VERSION ""

NS_ :

BS_:

BU_: Button_Panel_8 Joystick_JS6000 Display ESX_4CM_A Engine

BO_ 3221225472 VECTOR__INDEPENDENT_SIG_MSG: 0 Vector__XXX
 SG_ Button_State_09 : 24|2@1+ (1,0) [0|0] ""  ESX_4CM_A
 SG_ Button_State_10 : 26|2@1+ (1,0) [0|0] ""  ESX_4CM_A
 SG_ Button_State_11 : 28|2@1+ (1,0) [0|0] ""  ESX_4CM_A
 SG_ Button_State_12 : 30|2@1+ (1,0) [0|0] ""  ESX_4CM_A
 SG_ Joystick1XAxisNeutralPosStatus : 0|2@1+ (1,0) [0|3] ""  ESX_4CM_A
 SG_ Jystck1XAxsLvrLftNgtvePosStatus : 2|2@1+ (1,0) [0|3] ""  ESX_4CM_A
 SG_ Jystck1XAxsLvrRghtPstvPosStatus : 4|2@1+ (1,0) [0|3] ""  ESX_4CM_A
 SG_ Joystick1XAxisDetentPosStatus : 38|2@1+ (1,0) [0|3] ""  ESX_4CM_A
 SG_ Joystick1XAxisPos : 6|10@1+ (0.1,0) [0|102] "%"  ESX_4CM_A
 SG_ Joystick1Button12PressedStatus : 56|2@1+ (1,0) [0|3] ""  ESX_4CM_A
 SG_ Joystick1Button11PressedStatus : 58|2@1+ (1,0) [0|3] ""  ESX_4CM_A
 SG_ Joystick1Button10PressedStatus : 60|2@1+ (1,0) [0|3] ""  ESX_4CM_A
 SG_ Joystick1Button9PressedStatus : 62|2@1+ (1,0) [0|3] ""  ESX_4CM_A
 SG_ Joystick1Button8PressedStatus : 48|2@1+ (1,0) [0|3] ""  ESX_4CM_A
 SG_ Joystick1Button7PressedStatus : 50|2@1+ (1,0) [0|3] ""  ESX_4CM_A
 SG_ Joystick1YAxisDetentPosStatus : 36|2@1+ (1,0) [0|3] ""  ESX_4CM_A

BO_ 2565841155 E31_LIGHTS: 8 ESX_4CM_A
 SG_ BTN08_IND_SR m177 : 16|8@1+ (1,0) [0|0] ""  Button_Panel_8
 SG_ BTN01_IND_Aux1 m176 : 8|8@1+ (1,0) [0|0] ""  Button_Panel_8
 SG_ E1_IND_MUX M : 0|8@1+ (1,0) [0|0] ""  Button_Panel_8
 SG_ BTN_BACKLIGHT m136 : 8|1@1+ (1,0) [0|0] ""  Button_Panel_8
 SG_ BTN02_IND_AutoUL m176 : 16|8@1+ (1,0) [0|0] "" Vector__XXX
 SG_ BTN03_IND_SB_OP m176 : 24|8@1+ (1,0) [0|0] "" Vector__XXX
 SG_ BTN04_IND_Lights m176 : 32|8@1+ (1,0) [0|0] "" Vector__XXX
 SG_ BTN05_IND_PA m176 : 40|8@1+ (1,0) [0|0] "" Vector__XXX
 SG_ BTN06_IND_ManUL m176 : 48|8@1+ (1,0) [0|0] "" Vector__XXX
 SG_ BTN07_IND_SB_CL m176 : 56|8@1+ (1,0) [0|0] "" Vector__XXX

BO_ 2566889889 E1_BTN_STATUS: 8 Button_Panel_8
 SG_ BTN01_Aux1 m32 : 8|2@1+ (1,0) [0|0] ""  ESX_4CM_A
 SG_ BTN08_SR m32 : 22|2@1+ (1,0) [0|0] ""  ESX_4CM_A
 SG_ BTN07_SB_CL m32 : 20|2@1+ (1,0) [0|0] ""  ESX_4CM_A
 SG_ BNT06_ManUL m32 : 18|2@1+ (1,0) [0|0] ""  ESX_4CM_A
 SG_ BTN05_PA m32 : 16|2@1+ (1,0) [0|0] ""  ESX_4CM_A
 SG_ BTN04_Lights m32 : 14|2@1+ (1,0) [0|0] ""  ESX_4CM_A
 SG_ BTN03_SB_OP m32 : 12|2@1+ (1,0) [0|0] ""  ESX_4CM_A
 SG_ BTN02_AutoUL m32 : 10|2@1+ (1,0) [0|0] ""  ESX_4CM_A
 SG_ MUX M : 0|8@1+ (1,0) [0|0] ""  ESX_4CM_A

BO_ 2566849565 DISP_CMD2: 8 Display
 SG_ PROP_SetCCMax : 32|1@1+ (1,0) [0|0] ""  ESX_4CM_A
 SG_ FS_SpeedCmd : 56|8@1+ (1,0) [0|0] "%"  ESX_4CM_A

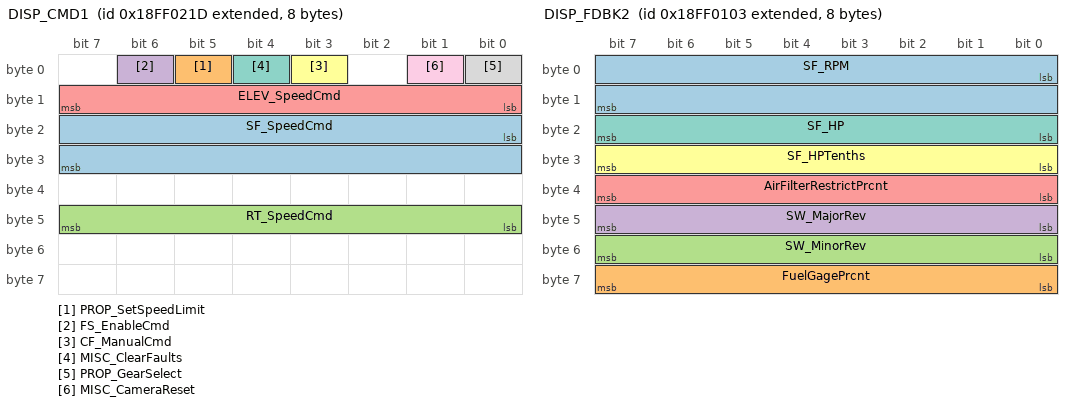
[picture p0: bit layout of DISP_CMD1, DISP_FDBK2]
BO_ 2566849053 DISP_CMD1: 8 Display
 SG_ SF_SpeedCmd : 16|16@1+ (1,0) [0|10000] "RPM"  ESX_4CM_A
 SG_ PROP_SetSpeedLimit : 5|1@1+ (1,0) [0|0] ""  ESX_4CM_A
 SG_ RT_SpeedCmd : 40|8@1+ (1,0) [0|100] "%"  ESX_4CM_A
 SG_ FS_EnableCmd : 6|1@1+ (1,0) [0|0] ""  ESX_4CM_A
 SG_ ELEV_SpeedCmd : 8|8@1+ (1,0) [0|100] "%"  ESX_4CM_A
 SG_ CF_ManualCmd : 3|1@1+ (1,0) [0|0] ""  ESX_4CM_A
 SG_ MISC_ClearFaults : 4|1@1+ (1,0) [0|0] ""  ESX_4CM_A
 SG_ PROP_GearSelect : 0|1@1+ (1,0) [0|0] ""  ESX_4CM_A
 SG_ MISC_CameraReset : 1|1@1+ (1,0) [0|0] ""  ESX_4CM_A

BO_ 2566848515 DISP_FDBK1: 8 ESX_4CM_A
 SG_ HYDOIL_Temp : 48|16@1+ (1,0) [0|255] "degrees C" Vector__XXX
 SG_ HYDOIL_LevelLow : 20|1@1+ (1,0) [0|1] ""  Display
 SG_ HC_ReliefPressure : 19|1@1+ (1,0) [0|1] ""  Display
 SG_ JS_NeutralState : 18|1@1+ (1,0) [0|1] ""  Display
 SG_ CF_Sen3OvrTmp : 47|1@1+ (1,0) [0|1] ""  Display
 SG_ CD_Sen2OvrTmp : 46|1@1+ (1,0) [0|1] ""  Display
 SG_ CF_Sen1OvrTmp : 45|1@1+ (1,0) [0|1] ""  Display
 SG_ CF_ManualStatus : 44|1@1+ (1,0) [0|1] ""  Display
 SG_ CF_DIR : 43|1@1+ (1,0) [0|1] ""  Display
 SG_ PROP_SpeedLimitStatus : 41|1@1+ (1,0) [0|1] ""  Display
 SG_ SR_Status : 39|1@1+ (1,0) [0|1] ""  Display
 SG_ AUGER_Status : 38|1@1+ (1,0) [0|1] ""  Display
 SG_ SHAFT_Status : 37|1@1+ (1,0) [0|1] ""  Display
 SG_ LIGHTS_WORKStatus : 36|1@1+ (1,0) [0|1] ""  Display
 SG_ LIGHTS_HDLTStatus : 35|1@1+ (1,0) [0|1] ""  Display
 SG_ ENGINE_Status : 34|1@1+ (1,0) [0|1] ""  Display
 SG_ ELEV_Status : 33|1@1+ (1,0) [0|1] ""  Display
 SG_ SF_Status : 32|1@1+ (1,0) [0|1] ""  Display
 SG_ PROP_SpeedX10 : 24|8@1+ (1,0) [0|0] "MPH x 10"  Display
 SG_ PROP_NeutralSafeInd : 23|1@1+ (1,0) [0|1] ""  Display
 SG_ MISC_BrakeStatus : 22|1@1+ (1,0) [0|1] ""  Display
 SG_ MISC_DoorStatus : 21|1@1+ (1,0) [0|1] ""  Display
 SG_ FUEL_LevelLow : 17|1@1+ (1,0) [0|1] ""  Display
 SG_ AIRFILT_ServiceRqd : 16|1@1+ (1,0) [0|1] ""  Display
 SG_ FUEL_FuelGage2 : 8|8@1+ (1,0) [0|0] "UINT8"  Display
 SG_ AIRFILT_Restriction : 0|8@1+ (1,0) [0|0] "UINT8"  Display

BO_ 2566848771 DISP_FDBK2: 8 ESX_4CM_A
 SG_ SF_RPM : 0|16@1- (1,0) [0|0] "RPM"  Display
 SG_ FuelGagePrcnt : 56|8@1+ (1,0) [0|0] "%"  Display
 SG_ SW_MinorRev : 48|8@1- (1,0) [0|0] ""  Display
 SG_ SW_MajorRev : 40|8@1- (1,0) [0|0] ""  Display
 SG_ AirFilterRestrictPrcnt : 32|8@1+ (1,0) [0|0] "%"  Display
 SG_ SF_HPTenths : 24|8@1- (1,0) [0|0] ""  Display
 SG_ SF_HP : 16|8@1- (1,0) [0|0] ""  Display

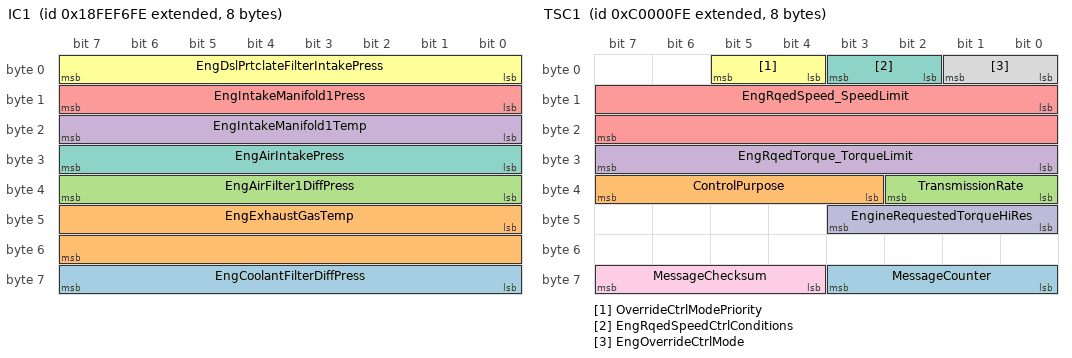
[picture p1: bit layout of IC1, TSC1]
BO_ 2566846206 IC1: 8 Engine
 SG_ EngCoolantFilterDiffPress : 56|8@1+ (0.5,0) [0|125] "kPa"  ESX_4CM_A
 SG_ EngExhaustGasTemp : 40|16@1+ (0.03125,-273) [4294967023|1734.96875] "deg C"  ESX_4CM_A
 SG_ EngAirFilter1DiffPress : 32|8@1+ (0.05,0) [0|12.5] "kPa"  ESX_4CM_A
 SG_ EngIntakeManifold1Temp : 16|8@1+ (1,-40) [4294967256|210] "deg C"  ESX_4CM_A
 SG_ EngIntakeManifold1Press : 8|8@1+ (2,0) [0|500] "kPa"  ESX_4CM_A
 SG_ EngDslPrtclateFilterIntakePress : 0|8@1+ (0.5,0) [0|125] "kPa"  ESX_4CM_A
 SG_ EngAirIntakePress : 24|8@1+ (2,0) [0|500] "kPa"  ESX_4CM_A

BO_ 2348810494 TSC1: 8 ESX_4CM_A
 SG_ MessageCounter : 56|4@1+ (1,0) [0|15] "" Vector__XXX
 SG_ ControlPurpose : 35|5@1+ (1,0) [0|31] "" Vector__XXX
 SG_ TransmissionRate : 32|3@1+ (1,0) [0|7] "" Vector__XXX
 SG_ EngRqedTorque_TorqueLimit : 24|8@1+ (1,-125) [4294967171|125] "%" Vector__XXX
 SG_ EngRqedSpeed_SpeedLimit : 8|16@1+ (0.125,0) [0|8031.875] "rpm"  Engine
 SG_ OverrideCtrlModePriority : 4|2@1+ (1,0) [0|3] "" Vector__XXX
 SG_ EngRqedSpeedCtrlConditions : 2|2@1+ (1,0) [0|3] "" Vector__XXX
 SG_ EngOverrideCtrlMode : 0|2@1+ (1,0) [0|3] "" Vector__XXX
 SG_ MessageChecksum : 60|4@1+ (1,0) [0|15] "" Vector__XXX
 SG_ EngineRequestedTorqueHiRes : 40|4@1+ (0.125,0) [0|0.875] "%" Vector__XXX

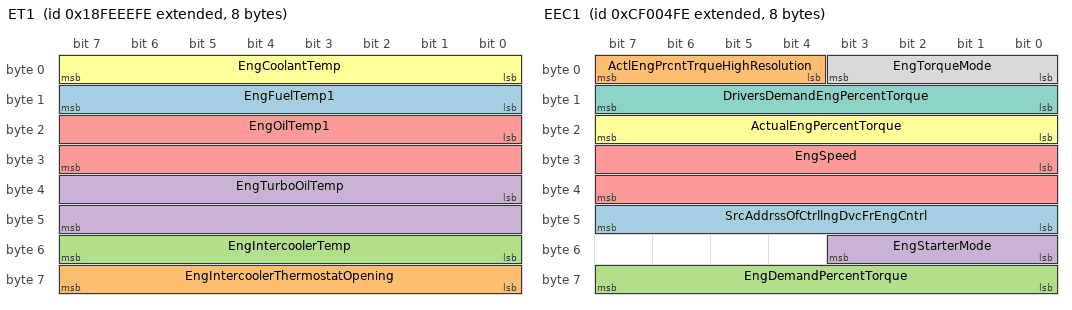
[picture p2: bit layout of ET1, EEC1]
BO_ 2566844158 ET1: 8 Engine
 SG_ EngFuelTemp1 : 8|8@1+ (1,-40) [4294967256|210] "deg C"  ESX_4CM_A
 SG_ EngIntercoolerThermostatOpening : 56|8@1+ (0.4,0) [0|100] "%"  ESX_4CM_A
 SG_ EngIntercoolerTemp : 48|8@1+ (1,-40) [4294967256|210] "deg C"  ESX_4CM_A
 SG_ EngTurboOilTemp : 32|16@1+ (0.03125,-273) [4294967023|1734.96875] "deg C"  ESX_4CM_A
 SG_ EngOilTemp1 : 16|16@1+ (0.03125,-273) [4294967023|1734.96875] "deg C"  ESX_4CM_A
 SG_ EngCoolantTemp : 0|8@1+ (0.03125,-273) [4294967023|-265.03125] "deg C"  ESX_4CM_A

BO_ 2364540158 EEC1: 8 Engine
 SG_ SrcAddrssOfCtrllngDvcFrEngCntrl : 40|8@1+ (1,0) [0|255] "" Vector__XXX
 SG_ ActlEngPrcntTrqueHighResolution : 4|4@1+ (0.125,0) [0|0.875] "%" Vector__XXX
 SG_ EngDemandPercentTorque : 56|8@1+ (1,-125) [4294967171|125] "%" Vector__XXX
 SG_ EngStarterMode : 48|4@1+ (1,0) [0|15] "" Vector__XXX
 SG_ EngSpeed : 24|16@1+ (0.125,0) [0|8031.875] "rpm"  ESX_4CM_A,Display
 SG_ ActualEngPercentTorque : 16|8@1+ (1,-125) [4294967171|125] "%" Vector__XXX
 SG_ DriversDemandEngPercentTorque : 8|8@1+ (1,-125) [4294967171|125] "%" Vector__XXX
 SG_ EngTorqueMode : 0|4@1+ (1,0) [0|15] "" Vector__XXX

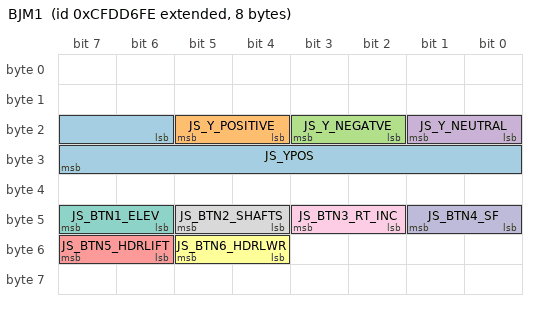
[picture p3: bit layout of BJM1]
BO_ 2365445886 BJM1: 8 Joystick_JS6000
 SG_ JS_YPOS : 22|10@1+ (0.1,0) [0|102] "%"  ESX_4CM_A
 SG_ JS_Y_POSITIVE : 20|2@1+ (1,0) [0|3] ""  ESX_4CM_A
 SG_ JS_Y_NEGATVE : 18|2@1+ (1,0) [0|3] ""  ESX_4CM_A
 SG_ JS_Y_NEUTRAL : 16|2@1+ (1,0) [0|3] ""  ESX_4CM_A
 SG_ JS_BTN5_HDRLIFT : 54|2@1+ (1,0) [0|3] ""  ESX_4CM_A
 SG_ JS_BTN6_HDRLWR : 52|2@1+ (1,0) [0|3] ""  ESX_4CM_A
 SG_ JS_BTN1_ELEV : 46|2@1+ (1,0) [0|3] ""  ESX_4CM_A
 SG_ JS_BTN2_SHAFTS : 44|2@1+ (1,0) [0|3] ""  ESX_4CM_A
 SG_ JS_BTN3_RT_INC : 42|2@1+ (1,0) [0|3] ""  ESX_4CM_A
 SG_ JS_BTN4_SF : 40|2@1+ (1,0) [0|3] ""  ESX_4CM_A

CM_ SG_ 3221225472 Joystick1XAxisNeutralPosStatus "Reports when the current joystick position is in the neutral position for that axis of travel.";
CM_ SG_ 3221225472 Jystck1XAxsLvrLftNgtvePosStatus "Reports when the current joystick position is on the negative travel side (back, left, counterclockwise, down) relative to the";
CM_ SG_ 3221225472 Jystck1XAxsLvrRghtPstvPosStatus "Reports when the current joystick position is on the positive travel side (forward, right, clockwise, up) relative to the";
CM_ SG_ 3221225472 Joystick1XAxisDetentPosStatus "Reports when the current joystick position is in the detent position for that axis of travel.";
CM_ SG_ 3221225472 Joystick1XAxisPos "The position of the joystick in the relative motion of travel from the neutral position.";
CM_ SG_ 3221225472 Joystick1Button12PressedStatus "Reports when the joystick button has been pressed.";
CM_ SG_ 3221225472 Joystick1Button11PressedStatus "Reports when the joystick button has been pressed.";
CM_ SG_ 3221225472 Joystick1Button10PressedStatus "Reports when the joystick button has been pressed.";
CM_ SG_ 3221225472 Joystick1Button9PressedStatus "Reports when the joystick button has been pressed.";
CM_ SG_ 3221225472 Joystick1Button8PressedStatus "Reports when the joystick button has been pressed.";
CM_ SG_ 3221225472 Joystick1Button7PressedStatus "Reports when the joystick button has been pressed.";
CM_ SG_ 3221225472 Joystick1YAxisDetentPosStatus "Reports when the current joystick position is in the detent position for that axis of travel.";
CM_ BO_ 2565841155 "Button Panel LED Indicator Controls";
CM_ SG_ 2565841155 BTN08_IND_SR "Stick Remover - Button 8 LED Control";
CM_ SG_ 2565841155 BTN01_IND_Aux1 "Auxillary - Button 1 LED Control";
CM_ SG_ 2565841155 BTN_BACKLIGHT "Backlight Control";
CM_ SG_ 2565841155 BTN02_IND_AutoUL "Auger Auto Unload - Button 2 LED Control";
CM_ SG_ 2565841155 BTN03_IND_SB_OP "Stick Box Open - Button 3 LED Control";
CM_ SG_ 2565841155 BTN04_IND_Lights "Light Selector - Button 4 LED Control";
CM_ SG_ 2565841155 BTN05_IND_PA "Power Assist Enable - Button 5 LED Control";
CM_ SG_ 2565841155 BTN06_IND_ManUL "Auger Manual Unload - Button 6 LED Control";
CM_ SG_ 2565841155 BTN07_IND_SB_CL "Stick Box Close - Button 7 LED Control";
CM_ BO_ 2566889889 "Button Panel Button States";
CM_ SG_ 2566889889 BTN01_Aux1 "Auxillary 1 - Button 01 State";
CM_ SG_ 2566889889 BTN08_SR "Stick Remover - Button 08 State";
CM_ SG_ 2566889889 BTN07_SB_CL "Stick Box Close - Button 07 State";
CM_ SG_ 2566889889 BNT06_ManUL "Auger Manual Unload - Button 06 State";
CM_ SG_ 2566889889 BTN05_PA "Power Assist Enable - Button 05 State";
CM_ SG_ 2566889889 BTN04_Lights "Light Selector - Button 04 State";
CM_ SG_ 2566889889 BTN03_SB_OP "Stick Box Open - Button 03 State";
CM_ SG_ 2566889889 BTN02_AutoUL "Auger Auto Unload - Button 02 State";
CM_ BO_ 2566849565 "General UI Machine Parameters 1";
CM_ SG_ 2566849565 PROP_SetCCMax "Momentary Input - Enable/Disable CC and Set CC Max Speed";
CM_ SG_ 2566849565 FS_SpeedCmd "Front Sweeps Speed Command";
CM_ BO_ 2566849053 "General UI Machine Parameters 2";
CM_ SG_ 2566849053 SF_SpeedCmd "Suction Fan Speed Command";
CM_ SG_ 2566849053 PROP_SetSpeedLimit "Toggled Input - Enable/Disable 47.5% Max Joystick Position";
CM_ SG_ 2566849053 RT_SpeedCmd "Rotary Trap Speed Command";
CM_ SG_ 2566849053 FS_EnableCmd "Toggled Input - Enable/Disable Front Sweeps";
CM_ SG_ 2566849053 ELEV_SpeedCmd "Elevator Speed Command";
CM_ SG_ 2566849053 CF_ManualCmd "Momentary Input - Manual Fan Reversal Command";
CM_ SG_ 2566849053 MISC_ClearFaults "Momentary Input - Clear Machine Faults";
CM_ SG_ 2566849053 PROP_GearSelect "Toggled Input -Toggle High/Low Gear";
CM_ BO_ 2566848515 "General UI Machine Feedback 1";
CM_ SG_ 2566848515 HYDOIL_Temp "Hydraulic Oil Temperature - degrees C";
CM_ SG_ 2566848515 HYDOIL_LevelLow "Hydraulic Oil Level Low Indicator";
CM_ SG_ 2566848515 HC_ReliefPressure "Header Relief Pressure Switch Status";
CM_ SG_ 2566848515 JS_NeutralState "Joystick Neutral Position Status";
CM_ SG_ 2566848515 CF_Sen3OvrTmp "Cooling Fan - Sensor 3 Overtemp Indicator";
CM_ SG_ 2566848515 CD_Sen2OvrTmp "Cooling Fan - Sensor 2 Overtemp Indicator";
CM_ SG_ 2566848515 CF_Sen1OvrTmp "Cooling Fan - Sensor 1 Overtemp Indicator";
CM_ SG_ 2566848515 CF_ManualStatus "Cooling Fan - Manual Reverse Status";
CM_ SG_ 2566848515 CF_DIR "Cooling Fan - Fan Direction";
CM_ SG_ 2566848515 PROP_SpeedLimitStatus "Max Joystick Position (47.5%) Status";
CM_ SG_ 2566848515 SR_Status "Stick Remover Status";
CM_ SG_ 2566848515 AUGER_Status "Auger Status";
CM_ SG_ 2566848515 SHAFT_Status "Cleaning Chains / Shaft Drive On/Off Status";
CM_ SG_ 2566848515 LIGHTS_WORKStatus "Worklights On/Off Status";
CM_ SG_ 2566848515 LIGHTS_HDLTStatus "Headlights On/Off Status";
CM_ SG_ 2566848515 ENGINE_Status "Taillights On/Off Status";
CM_ SG_ 2566848515 ELEV_Status "Elevator On/Off Status";
CM_ SG_ 2566848515 SF_Status "Suction Fan On/Off Status";
CM_ SG_ 2566848515 PROP_SpeedX10 "Ground Speed (x10)";
CM_ SG_ 2566848515 PROP_NeutralSafeInd "Machine in Neutral and Safe State (Engine Start Safe) Indicator";
CM_ SG_ 2566848515 MISC_BrakeStatus "Brake On/Off Status";
CM_ SG_ 2566848515 MISC_DoorStatus "Door Open/Closed Status";
CM_ SG_ 2566848515 FUEL_LevelLow "Fuel Level Low Indicator";
CM_ SG_ 2566848515 AIRFILT_ServiceRqd "Air Filter Service Required Indicator";
CM_ SG_ 2566848515 FUEL_FuelGage2 "0-255 Value (0-100%)";
CM_ SG_ 2566848515 AIRFILT_Restriction "0-255 Value (0-100%)";
CM_ BO_ 2566848771 "General UI Machine Feedback 2";
CM_ SG_ 2566848771 SF_RPM "Suction Fan Speed (RPM)";
CM_ SG_ 2566848771 FuelGagePrcnt "Fuel Gauge Level (Percent)";
CM_ SG_ 2566848771 SW_MinorRev "Software Version - Minor ";
CM_ SG_ 2566848771 SW_MajorRev "Software Version - Major";
CM_ SG_ 2566848771 AirFilterRestrictPrcnt "Air Restriction Gauge Percent";
CM_ BO_ 2566846206 "Intake/Exhaust Conditions 1";
CM_ SG_ 2566846206 EngCoolantFilterDiffPress "Change in coolant pressure, measured across the filter, due to the filter and any accumulation of solid or semisolid matter";
CM_ SG_ 2566846206 EngExhaustGasTemp "Temperature of combustion byproducts leaving the engine.";
CM_ SG_ 2566846206 EngAirFilter1DiffPress "Change in engine air system pressure, measured across the filter, due to the filter and any accumulation of solid foreign";
CM_ SG_ 2566846206 EngIntakeManifold1Temp "Temperature of pre-combustion air found in intake manifold of engine air supply system.";
CM_ SG_ 2566846206 EngIntakeManifold1Press "The gage pressure measurement of the air intake manifold.";
CM_ SG_ 2566846206 EngDslPrtclateFilterIntakePress "Exhaust back pressure as a result of particle accumulation on filter media placed in the exhaust stream.";
CM_ SG_ 2566846206 EngAirIntakePress "Absolute air pressure at input port to intake manifold or air box.";
CM_ BO_ 2348810494 "Torque/Speed Control 1";
CM_ SG_ 2348810494 MessageCounter "The message counter is used to detect situations where the transmitting ECU malfunction repeats the same frame all the time.";
CM_ SG_ 2348810494 ControlPurpose "State signal which indicates which control mode the sending device is using to generate the TSC1 command.";
CM_ SG_ 2348810494 TransmissionRate "This parameter indicates the transmission rate at which the sending device will transmit the TSC1 message.";
CM_ SG_ 2348810494 EngRqedTorque_TorqueLimit "Parameter provided to the engine or retarder in the torque/speed control message for controlling or limiting the output torque.";
CM_ SG_ 2348810494 EngRqedSpeed_SpeedLimit "Parameter provided to the engine from external sources in the torque/speed control message.";
CM_ SG_ 2348810494 EngRqedSpeedCtrlConditions "This mode tells the engine control system the governor characteristics that are desired during speed control.";
CM_ SG_ 2348810494 MessageChecksum "The checksum is used to verify the signal path from the transmitting device to the receiving device.";
CM_ SG_ 2348810494 EngineRequestedTorqueHiRes "This parameter displays an additional torque in percent of the reference engine torque.";
CM_ BO_ 2566844158 "Engine Temperature 1";
CM_ SG_ 2566844158 EngFuelTemp1 "Temperature of fuel (or gas) passing through the first fuel control system.";
CM_ SG_ 2566844158 EngIntercoolerThermostatOpening "The current position of the thermostat used to regulate the temperature of the engine intercooler.";
CM_ SG_ 2566844158 EngIntercoolerTemp "Temperature of liquid found in the intercooler located after the turbocharger.";
CM_ SG_ 2566844158 EngTurboOilTemp "Temperature of the turbocharger lubricant.";
CM_ SG_ 2566844158 EngOilTemp1 "Temperature of the engine lubricant.";
CM_ SG_ 2566844158 EngCoolantTemp "Temperature of liquid found in engine cooling system.";
CM_ BO_ 2364540158 "Electronic Engine Controller 1";
CM_ SG_ 2364540158 SrcAddrssOfCtrllngDvcFrEngCntrl "The source address of the SAE J1939 device currently controlling the engine.";
CM_ SG_ 2364540158 ActlEngPrcntTrqueHighResolution "This parameter displays an additional torque in percent of the reference engine torque.";
CM_ SG_ 2364540158 EngDemandPercentTorque "The requested torque output of the engine by all dynamic internal inputs, including smoke control, noise control and low";
CM_ SG_ 2364540158 EngStarterMode "There are several phases in a starting action and different reasons why a start cannot take place.";
CM_ SG_ 2364540158 EngSpeed "Actual engine speed which is calculated over a minimum crankshaft angle of 720 degrees divided by the number of cylinders.";
CM_ SG_ 2364540158 ActualEngPercentTorque "The calculated output torque of the engine.";
CM_ SG_ 2364540158 DriversDemandEngPercentTorque "The requested torque output of the engine by the driver.";
CM_ SG_ 2364540158 EngTorqueMode "State signal which indicates which engine torque mode is currently generating, limiting, or controlling the torque.";
CM_ BO_ 2365445886 "Basic Joystick Message 1";
CM_ SG_ 2365445886 JS_YPOS "The position of the joystick in the relative motion of travel from the neutral position.";
CM_ SG_ 2365445886 JS_Y_POSITIVE "Reports when the current joystick position is on the positive travel side (forward, right, clockwise, up) relative to the";
CM_ SG_ 2365445886 JS_Y_NEGATVE "Reports when the current joystick position is on the negative travel side (back, left, counterclockwise, down) relative to the";
CM_ SG_ 2365445886 JS_Y_NEUTRAL "Reports when the current joystick position is in the neutral position for that axis of travel.";
CM_ SG_ 2365445886 JS_BTN5_HDRLIFT "Reports when the joystick button has been pressed.";
CM_ SG_ 2365445886 JS_BTN6_HDRLWR "Reports when the joystick button has been pressed.";
CM_ SG_ 2365445886 JS_BTN1_ELEV "Elevator On/Off Control";
CM_ SG_ 2365445886 JS_BTN2_SHAFTS "Cleaning Chains On/Off Control";
CM_ SG_ 2365445886 JS_BTN3_RT_INC "Rotary Trap Speed Increase Control";
CM_ SG_ 2365445886 JS_BTN4_SF "Suction Fan On/Off Control";
BA_DEF_ SG_  "SigType" ENUM  "Default","Range","RangeSigned","ASCII","Discrete","Control","ReferencePGN","DTC","StringDelimiter","StringLength","StringLengthControl";
BA_DEF_ SG_  "GenSigSendType" ENUM  "Cyclic","OnWrite","reserved","OnChange","reserved","reserved","reserved","NoSigSendType";
BA_DEF_ SG_  "GenSigILSupport" ENUM  "Yes","No";
BA_DEF_ SG_  "GenSigEVName" STRING ;
BA_DEF_ SG_  "SPN" INT 0 524287;
BA_DEF_ BO_  "GenMsgILSupport" ENUM  "Yes","No";
BA_DEF_ BO_  "GenMsgRequestable" INT 0 1;
BA_DEF_ BO_  "GenMsgSendType" ENUM  "cyclic","reserved","cyclicIfActive","reserved","reserved","reserved","reserved","reserved","noMsgSendType";
BA_DEF_ BO_  "VFrameFormat" ENUM  "StandardCAN","ExtendedCAN","reserved","J1939PG";
BA_DEF_ BO_  "GenMsgCycleTime" INT 0 3600000;
BA_DEF_ BU_  "NmStationAddress" INT 0 255;
BA_DEF_ BU_  "NmJ1939IndustryGroup" INT 0 7;
BA_DEF_ BU_  "NmJ1939System" INT 0 127;
BA_DEF_ BU_  "NmJ1939Function" INT 0 255;
BA_DEF_ BU_  "NmJ1939FunctionInstance" INT 0 7;
BA_DEF_  "DatabaseVersion" STRING ;
BA_DEF_  "BusType" STRING ;
BA_DEF_  "ProtocolType" STRING ;
BA_DEF_  "SAE_J1939_75_SpecVersion" STRING ;
BA_DEF_  "SAE_J1939_21_SpecVersion" STRING ;
BA_DEF_  "SAE_J1939_73_SpecVersion" STRING ;
BA_DEF_  "SAE_J1939_71_SpecVersion" STRING ;
BA_DEF_DEF_  "SigType" "Default";
BA_DEF_DEF_  "GenSigSendType" "NoSigSendType";
BA_DEF_DEF_  "GenSigILSupport" "Yes";
BA_DEF_DEF_  "GenSigEVName" "Env@Nodename_@Signame";
BA_DEF_DEF_  "SPN" 0;
BA_DEF_DEF_  "GenMsgILSupport" "Yes";
BA_DEF_DEF_  "GenMsgRequestable" 1;
BA_DEF_DEF_  "GenMsgSendType" "noMsgSendType";
BA_DEF_DEF_  "VFrameFormat" "J1939PG";
BA_DEF_DEF_  "GenMsgCycleTime" 0;
BA_DEF_DEF_  "NmStationAddress" 254;
BA_DEF_DEF_  "NmJ1939IndustryGroup" 0;
BA_DEF_DEF_  "NmJ1939System" 0;
BA_DEF_DEF_  "NmJ1939Function" 0;
BA_DEF_DEF_  "NmJ1939FunctionInstance" 0;
BA_DEF_DEF_  "DatabaseVersion" "";
BA_DEF_DEF_  "BusType" "";
BA_DEF_DEF_  "ProtocolType" "";
BA_DEF_DEF_  "SAE_J1939_75_SpecVersion" "";
BA_DEF_DEF_  "SAE_J1939_21_SpecVersion" "";
BA_DEF_DEF_  "SAE_J1939_73_SpecVersion" "";
BA_DEF_DEF_  "SAE_J1939_71_SpecVersion" "";
BA_ "DatabaseVersion" "7.2";
BA_ "BusType" "CAN";
BA_ "ProtocolType" "J1939";
BA_ "SAE_J1939_75_SpecVersion" "2005-10";
BA_ "SAE_J1939_21_SpecVersion" "2006-10";
BA_ "SAE_J1939_73_SpecVersion" "2009-09";
BA_ "SAE_J1939_71_SpecVersion" "2009-09";
BA_ "SPN" SG_ 2565841155 BTN08_IND_SR 520656;
BA_ "SPN" SG_ 2565841155 BTN01_IND_Aux1 520601;
BA_ "SPN" SG_ 2565841155 E1_IND_MUX 520600;
BA_ "SPN" SG_ 2565841155 BTN_BACKLIGHT 520609;
BA_ "SPN" SG_ 2566889889 BTN01_Aux1 520661;
BA_ "SPN" SG_ 2566889889 BTN08_SR 520668;
BA_ "SPN" SG_ 2566889889 BTN07_SB_CL 520667;
BA_ "SPN" SG_ 2566889889 BNT06_ManUL 520666;
BA_ "SPN" SG_ 2566889889 BTN05_PA 520665;
BA_ "SPN" SG_ 2566889889 BTN04_Lights 520664;
BA_ "SPN" SG_ 2566889889 BTN03_SB_OP 520663;
BA_ "SPN" SG_ 2566889889 BTN02_AutoUL 520662;
BA_ "SPN" SG_ 2566889889 MUX 520660;
BA_ "SPN" SG_ 2566849565 PROP_SetCCMax 520546;
BA_ "SPN" SG_ 2566849565 FS_SpeedCmd 520545;
BA_ "SPN" SG_ 2566849053 SF_SpeedCmd 520543;
BA_ "SPN" SG_ 2566849053 PROP_SetSpeedLimit 520540;
BA_ "SPN" SG_ 2566849053 RT_SpeedCmd 520544;
BA_ "SPN" SG_ 2566849053 FS_EnableCmd 520541;
BA_ "SPN" SG_ 2566849053 ELEV_SpeedCmd 520542;
BA_ "SPN" SG_ 2566849053 CF_ManualCmd 520538;
BA_ "SPN" SG_ 2566849053 MISC_ClearFaults 520539;
BA_ "SPN" SG_ 2566849053 PROP_GearSelect 520536;
BA_ "SPN" SG_ 2566849053 MISC_CameraReset 520537;
BA_ "SPN" SG_ 2566848515 HYDOIL_Temp 520526;
BA_ "SPN" SG_ 2566848515 HYDOIL_LevelLow 520507;
BA_ "SPN" SG_ 2566848515 HC_ReliefPressure 520506;
BA_ "SPN" SG_ 2566848515 JS_NeutralState 520505;
BA_ "SPN" SG_ 2566848515 CF_Sen3OvrTmp 520524;
BA_ "SPN" SG_ 2566848515 CD_Sen2OvrTmp 520524;
BA_ "SPN" SG_ 2566848515 CF_Sen1OvrTmp 520523;
BA_ "SPN" SG_ 2566848515 CF_ManualStatus 520522;
BA_ "SPN" SG_ 2566848515 CF_DIR 520521;
BA_ "SPN" SG_ 2566848515 PROP_SpeedLimitStatus 520520;
BA_ "SPN" SG_ 2566848515 SR_Status 520519;
BA_ "SPN" SG_ 2566848515 AUGER_Status 520518;
BA_ "SPN" SG_ 2566848515 SHAFT_Status 520517;
BA_ "SPN" SG_ 2566848515 LIGHTS_WORKStatus 520516;
BA_ "SPN" SG_ 2566848515 LIGHTS_HDLTStatus 520515;
BA_ "SPN" SG_ 2566848515 ENGINE_Status 520514;
BA_ "SPN" SG_ 2566848515 ELEV_Status 520513;
BA_ "SPN" SG_ 2566848515 SF_Status 520512;
BA_ "SPN" SG_ 2566848515 PROP_SpeedX10 520511;
BA_ "SPN" SG_ 2566848515 PROP_NeutralSafeInd 520510;
BA_ "SPN" SG_ 2566848515 MISC_BrakeStatus 520509;
BA_ "SPN" SG_ 2566848515 MISC_DoorStatus 520508;
BA_ "SPN" SG_ 2566848515 FUEL_LevelLow 520503;
BA_ "SPN" SG_ 2566848515 AIRFILT_ServiceRqd 520502;
BA_ "SPN" SG_ 2566848515 FUEL_FuelGage2 524001;
BA_ "SPN" SG_ 2566848515 AIRFILT_Restriction 524012;
BA_ "SPN" SG_ 2566848771 SF_RPM 520528;
BA_ "SPN" SG_ 2566848771 FuelGagePrcnt 520535;
BA_ "SPN" SG_ 2566848771 SW_MinorRev 520534;
BA_ "SPN" SG_ 2566848771 SW_MajorRev 520533;
BA_ "SPN" SG_ 2566848771 AirFilterRestrictPrcnt 520532;
BA_ "SPN" SG_ 2566848771 SF_HPTenths 520531;
BA_ "SPN" SG_ 2566848771 SF_HP 520530;
BA_ "GenMsgSendType" BO_ 2566846206 0;
BA_ "GenMsgCycleTime" BO_ 2566846206 500;
BA_ "SigType" SG_ 2566846206 EngCoolantFilterDiffPress 1;
BA_ "SPN" SG_ 2566846206 EngCoolantFilterDiffPress 112;
BA_ "SigType" SG_ 2566846206 EngExhaustGasTemp 1;
BA_ "SPN" SG_ 2566846206 EngExhaustGasTemp 173;
BA_ "SigType" SG_ 2566846206 EngAirFilter1DiffPress 1;
BA_ "SPN" SG_ 2566846206 EngAirFilter1DiffPress 107;
BA_ "SigType" SG_ 2566846206 EngIntakeManifold1Temp 1;
BA_ "SPN" SG_ 2566846206 EngIntakeManifold1Temp 105;
BA_ "SigType" SG_ 2566846206 EngIntakeManifold1Press 1;
BA_ "SPN" SG_ 2566846206 EngIntakeManifold1Press 102;
BA_ "SigType" SG_ 2566846206 EngDslPrtclateFilterIntakePress 1;
BA_ "SPN" SG_ 2566846206 EngDslPrtclateFilterIntakePress 81;
BA_ "SigType" SG_ 2566846206 EngAirIntakePress 1;
BA_ "SPN" SG_ 2566846206 EngAirIntakePress 106;
BA_ "SPN" SG_ 2348810494 MessageCounter 4206;
BA_ "SPN" SG_ 2348810494 ControlPurpose 3350;
BA_ "SPN" SG_ 2348810494 TransmissionRate 3349;
BA_ "SigType" SG_ 2348810494 EngRqedTorque_TorqueLimit 1;
BA_ "SPN" SG_ 2348810494 EngRqedTorque_TorqueLimit 518;
BA_ "SigType" SG_ 2348810494 EngRqedSpeed_SpeedLimit 1;
BA_ "SPN" SG_ 2348810494 EngRqedSpeed_SpeedLimit 898;
BA_ "SPN" SG_ 2348810494 OverrideCtrlModePriority 897;
BA_ "SPN" SG_ 2348810494 EngRqedSpeedCtrlConditions 696;
BA_ "SPN" SG_ 2348810494 EngOverrideCtrlMode 695;
BA_ "SPN" SG_ 2348810494 MessageChecksum 4207;
BA_ "SPN" SG_ 2348810494 EngineRequestedTorqueHiRes 4191;
BA_ "GenMsgSendType" BO_ 2566844158 0;
BA_ "GenMsgCycleTime" BO_ 2566844158 1000;
BA_ "SigType" SG_ 2566844158 EngFuelTemp1 1;
BA_ "SPN" SG_ 2566844158 EngFuelTemp1 174;
BA_ "SigType" SG_ 2566844158 EngIntercoolerThermostatOpening 1;
BA_ "SPN" SG_ 2566844158 EngIntercoolerThermostatOpening 1134;
BA_ "SigType" SG_ 2566844158 EngIntercoolerTemp 1;
BA_ "SPN" SG_ 2566844158 EngIntercoolerTemp 52;
BA_ "SigType" SG_ 2566844158 EngTurboOilTemp 1;
BA_ "SPN" SG_ 2566844158 EngTurboOilTemp 176;
BA_ "SigType" SG_ 2566844158 EngOilTemp1 1;
BA_ "SPN" SG_ 2566844158 EngOilTemp1 175;
BA_ "SigType" SG_ 2566844158 EngCoolantTemp 1;
BA_ "SPN" SG_ 2566844158 EngCoolantTemp 1637;
BA_ "GenMsgSendType" BO_ 2364540158 0;
BA_ "GenMsgCycleTime" BO_ 2364540158 100;
BA_ "SigType" SG_ 2364540158 SrcAddrssOfCtrllngDvcFrEngCntrl 1;
BA_ "SPN" SG_ 2364540158 SrcAddrssOfCtrllngDvcFrEngCntrl 1483;
BA_ "SigType" SG_ 2364540158 ActlEngPrcntTrqueHighResolution 1;
BA_ "SPN" SG_ 2364540158 ActlEngPrcntTrqueHighResolution 4154;
BA_ "SigType" SG_ 2364540158 EngDemandPercentTorque 1;
BA_ "SPN" SG_ 2364540158 EngDemandPercentTorque 2432;
BA_ "SigType" SG_ 2364540158 EngStarterMode 4;
BA_ "SPN" SG_ 2364540158 EngStarterMode 1675;
BA_ "SigType" SG_ 2364540158 EngSpeed 1;
BA_ "SPN" SG_ 2364540158 EngSpeed 190;
BA_ "SigType" SG_ 2364540158 ActualEngPercentTorque 1;
BA_ "SPN" SG_ 2364540158 ActualEngPercentTorque 513;
BA_ "SigType" SG_ 2364540158 DriversDemandEngPercentTorque 1;
BA_ "SPN" SG_ 2364540158 DriversDemandEngPercentTorque 512;
BA_ "SigType" SG_ 2364540158 EngTorqueMode 4;
BA_ "SPN" SG_ 2364540158 EngTorqueMode 899;
BA_ "GenMsgSendType" BO_ 2365445886 0;
BA_ "GenMsgCycleTime" BO_ 2365445886 100;
BA_ "SigType" SG_ 2365445886 JS_YPOS 1;
BA_ "SPN" SG_ 2365445886 JS_YPOS 2661;
BA_ "SigType" SG_ 2365445886 JS_Y_POSITIVE 4;
BA_ "SPN" SG_ 2365445886 JS_Y_POSITIVE 2666;
BA_ "SigType" SG_ 2365445886 JS_Y_NEGATVE 4;
BA_ "SPN" SG_ 2365445886 JS_Y_NEGATVE 2671;
BA_ "SigType" SG_ 2365445886 JS_Y_NEUTRAL 4;
BA_ "SPN" SG_ 2365445886 JS_Y_NEUTRAL 2676;
BA_ "SigType" SG_ 2365445886 JS_BTN5_HDRLIFT 4;
BA_ "SPN" SG_ 2365445886 JS_BTN5_HDRLIFT 2689;
BA_ "SigType" SG_ 2365445886 JS_BTN6_HDRLWR 4;
BA_ "SPN" SG_ 2365445886 JS_BTN6_HDRLWR 2690;
BA_ "SigType" SG_ 2365445886 JS_BTN1_ELEV 4;
BA_ "SPN" SG_ 2365445886 JS_BTN1_ELEV 2685;
BA_ "SigType" SG_ 2365445886 JS_BTN2_SHAFTS 4;
BA_ "SPN" SG_ 2365445886 JS_BTN2_SHAFTS 2686;
BA_ "SigType" SG_ 2365445886 JS_BTN3_RT_INC 4;
BA_ "SPN" SG_ 2365445886 JS_BTN3_RT_INC 2687;
BA_ "SigType" SG_ 2365445886 JS_BTN4_SF 4;
BA_ "SPN" SG_ 2365445886 JS_BTN4_SF 2688;
BA_ "NmStationAddress" BU_ Button_Panel_8 161;
BA_ "NmStationAddress" BU_ Joystick_JS6000 51;
BA_ "NmStationAddress" BU_ Display 29;
BA_ "NmStationAddress" BU_ ESX_4CM_A 3;
BA_ "NmStationAddress" BU_ Engine 0;
VAL_ 2565841155 E1_IND_MUX 136 "Backlight Control" 176 "Button Group 1" 177 "Button Group 2" ;
VAL_ 2566889889 BTN01_Aux1 0 "OFF" 1 "PRESSED" ;
VAL_ 2566889889 BTN08_SR 0 "OFF" 1 "PRESSED" ;
VAL_ 2566889889 BTN07_SB_CL 0 "OFF" 1 "PRESSED" ;
VAL_ 2566889889 BNT06_ManUL 0 "OFF" 1 "PRESSED" ;
VAL_ 2566889889 BTN05_PA 0 "OFF" 1 "PRESSED" ;
VAL_ 2566889889 BTN04_Lights 0 "OFF" 1 "PRESSED" ;
VAL_ 2566889889 BTN03_SB_OP 0 "OFF" 1 "PRESSED" ;
VAL_ 2566889889 BTN02_AutoUL 0 "OFF" 1 "PRESSED" ;
VAL_ 2566889889 MUX 32 "MASTER" 33 "EXP_1" ;
VAL_ 2566849565 PROP_SetCCMax 0 "OFF" 1 "PRESSED" ;
VAL_ 2566849053 PROP_SetSpeedLimit 0 "OFF" 1 "PRESSED" ;
VAL_ 2566849053 CF_ManualCmd 0 "OFF" 1 "PRESSED" ;
VAL_ 2566849053 MISC_ClearFaults 0 "OFF" 1 "PRESSED" ;
VAL_ 2566849053 PROP_GearSelect 0 "OFF" 1 "PRESSED" ;
VAL_ 2566848515 HYDOIL_LevelLow 0 "Level OK" 1 "Level Low" ;
VAL_ 2566848515 HC_ReliefPressure 0 "Pressure OK" 1 "Relief Active" ;
VAL_ 2566848515 JS_NeutralState 0 "Out of Neutral" 1 "In Neutral" ;
VAL_ 2566848515 CF_Sen3OvrTmp 0 "Temp OK" 1 "Overtemp" ;
VAL_ 2566848515 CD_Sen2OvrTmp 0 "Temp OK" 1 "Overtemp" ;
VAL_ 2566848515 CF_Sen1OvrTmp 0 "Temp OK" 1 "Overtemp" ;
VAL_ 2566848515 CF_ManualStatus 0 "Not Enabled" 1 "Enabled" ;
VAL_ 2566848515 CF_DIR 0 "FWD" 1 "REVERSE" ;
VAL_ 2566848515 PROP_SpeedLimitStatus 0 "Not Enabled" 1 "Enabled" ;
VAL_ 2566848515 SR_Status 0 "Not Enabled" 1 "Enabled" ;
VAL_ 2566848515 AUGER_Status 0 "Not Enabled" 1 "Enabled" ;
VAL_ 2566848515 SHAFT_Status 0 "Not Enabled" 1 "Enabled" ;
VAL_ 2566848515 LIGHTS_WORKStatus 0 "OFF" 1 "ON" ;
VAL_ 2566848515 LIGHTS_HDLTStatus 0 "OFF" 1 "ON" ;
VAL_ 2566848515 ENGINE_Status 0 "OFF" 1 "ON" ;
VAL_ 2566848515 ELEV_Status 0 "Not Enabled" 1 "Enabled" ;
VAL_ 2566848515 SF_Status 0 "Not Enabled" 1 "Enabled" ;
VAL_ 2566848515 PROP_NeutralSafeInd 0 "Safe Netural Not Detected" 1 "Safe Netrual Detected" ;
VAL_ 2566848515 MISC_BrakeStatus 0 "Disengaged" 1 "Engaged" ;
VAL_ 2566848515 MISC_DoorStatus 0 "Door Closed" 1 "Door Open" ;
VAL_ 2566848515 FUEL_LevelLow 0 "Fuel Level OK" 1 "Fuel Level Low" ;
VAL_ 2566848515 AIRFILT_ServiceRqd 0 "FILTER OK" 1 "SERVICE REQ" ;
VAL_ 2348810494 MessageCounter 14 "Reserved" 13 "Reserved" 12 "Reserved" 11 "Reserved" 10 "Reserved" 9 "Reserved" 8 "Reserved" 15 "Not Available" ;
VAL_ 2348810494 ControlPurpose 5 "TemporaryPowerTrainControl" 4 "EngineProtection" 3 "RoadSpeedGovernor" 2 "PTOGovernor" 1 "CruiseControl" 0 "AcceleratorPedal" ;
VAL_ 2348810494 TransmissionRate 7 "UseStandardRate" 6 "25ms" 5 "50ms" 4 "100ms" 3 "250ms" 2 "500ms" 1 "750ms" 0 "1000ms" ;
VAL_ 2348810494 OverrideCtrlModePriority 3 "LowPriority" 2 "MdmPrrtyUsdFrPwrtrnCtrlOprtnsWh" 1 "HighPriority" 0 "HghstPrrtyUsdFrSttnsThtRqrImmdt" ;
VAL_ 2348810494 EngRqedSpeedCtrlConditions 2 "ThsCtrlCndtnHsBnOptmzdTMnmzRpmO" 3 "StbltyOptmzdFrDrvlnEnggdAnd_OrI" 1 "StbltyOptmzdFrDrvlnDsnggdAndNnl" 0 "ThsSpdGvrnrGnSlctnIsAdjstdTPrvd" ;
VAL_ 2348810494 EngOverrideCtrlMode 3 "Spd_TrqLmtCtrlLmtSpdAnd_OrTrqBs" 2 "TrqCtrlCntrlTrqTInclddDsrdTrqVl" 1 "SpdCtrlGvrnSpdTInclddDsrdSpdVle" 0 "OvrrdDsbldDsblAnyExstngCtrlCmdd" ;
VAL_ 2348810494 MessageChecksum 15 "Not Available" ;
VAL_ 2348810494 EngineRequestedTorqueHiRes 15 "Not Available" 14 "Not Available" 13 "Not Available" 12 "Not Available" 11 "Not Available" 10 "Not Available" 9 "Not Available" 8 "Not Available" ;
VAL_ 2364540158 ActlEngPrcntTrqueHighResolution 8 "1111NotAvailable" 7 "0875" 1 "0125" 0 "0000" ;
VAL_ 2364540158 EngStarterMode 15 "notAvailable" 14 "error" 12 "starterInhibitedReasonUnknown" 9 "1011Reserved" 8 "strtrInhbtdDueToStarterOvertemp" 7 "strtrInhbtdDToActiveImmobilizer" 6 "strtrInhbtdDTDrvlnEnggdOthrTrns" 5 "strtrInhbtdDTEngNtReadyForStart" 4 "strtrInhbtdDToEngAlreadyRunning" 3 "strtFnshdStrtrNtActvAftrHvngBnA" 2 "starterActiveGearEngaged" 1 "starterActiveGearNotEngaged" 0 "startNotRqed" ;
VAL_ 2364540158 EngTorqueMode 15 "Not available" 11 "Remote accelerator" 10 "Braking system" 9 "High speed governor" 8 "Torque limiting" 7 "ABS control" 6 "Transmission control" 5 "ASR control" 4 "Road speed governor" 3 "PTO governor" 2 "Cruise control" 1 "Accelerator pedal/operator selec" 0 "Low idle governor/no request (de" ;
VAL_ 2365445886 JS_Y_POSITIVE 3 "NotAvailable" 2 "ErrorIndicator" 1 "OnPositiveSideOfNeutral" 0 "NotOnPositiveSideOfNeutral" ;
VAL_ 2365445886 JS_Y_NEGATVE 3 "NotAvailable" 2 "ErrorIndicator" 1 "OnNegativeSideOfNeutral" 0 "NotOnNegativeSideOfNeutral" ;
VAL_ 2365445886 JS_Y_NEUTRAL 3 "NotAvailable" 2 "ErrorIndicator" 1 "InNeutralPos" 0 "NotInNeutralPos" ;
VAL_ 2365445886 JS_BTN5_HDRLIFT 3 "NotAvailable" 2 "ErrorIndicator" 1 "ButtonPressed" 0 "ButtonNotPressed" ;
VAL_ 2365445886 JS_BTN6_HDRLWR 3 "NotAvailable" 2 "ErrorIndicator" 1 "ButtonPressed" 0 "ButtonNotPressed" ;
VAL_ 2365445886 JS_BTN1_ELEV 3 "NotAvailable" 2 "ErrorIndicator" 1 "ButtonPressed" 0 "ButtonNotPressed" ;
VAL_ 2365445886 JS_BTN2_SHAFTS 3 "NotAvailable" 2 "ErrorIndicator" 1 "ButtonPressed" 0 "ButtonNotPressed" ;
VAL_ 2365445886 JS_BTN3_RT_INC 3 "NotAvailable" 2 "ErrorIndicator" 1 "ButtonPressed" 0 "ButtonNotPressed" ;
VAL_ 2365445886 JS_BTN4_SF 3 "NotAvailable" 2 "ErrorIndicator" 1 "ButtonPressed" 0 "ButtonNotPressed" ;
